# RT58X register map
Series: ARMv8-M Mainline; File version: 1.0
CPU: CM3 r0p0, little endian, MPU, no FPU, VTOR, 3 interrupt priority bits
Registers are 32-bit, read-write, reset 0x0 unless marked. A register's access mark holds for its fields unless they carry their own. Offsets are from the block's base; [hi:lo] are bit positions.

## TIMER1 — TIMER1 Register block
Base 0xA0800000
0x00 T1_LOAD_REG — The initial value of the timer. Also, the reload value when the timer is in periodic mode.
0x04 T1_VALUE_REG ro — The current value of the timer synchronized to the PCLK domain. Note that in cases where PCLK is slow, this value may significantly differ from the actual internal count.
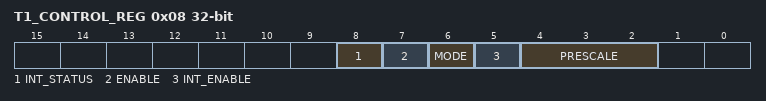
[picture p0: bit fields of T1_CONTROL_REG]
0x08 T1_CONTROL_REG — t1 control
  [8] INT_STATUS ro — Interrupt Status. 0: Timer interrupt is inactive 1: Timer interrupt active.
    0=B_8 (Interrupt Status. 0: Timer interrupt is inactive 1: Timer interrupt active.)
  [7] ENABLE — 0: Timer Disabled 1: Timer Enabled
    0=B_7 (0: Timer Disabled 1: Timer Enabled)
  [6] MODE — 0: Free running mode 1: Periodic mode.
    0=B_6 (0: Free running mode 1: Periodic mode.)
  [5] INT_ENABLE — 0: Timer interrupt disable 1: Timer interrupt enable.
    0=B_5 (0: Timer interrupt disable 1: Timer interrupt enable.)
  [4:2] PRESCALE — 0: clock is divided by one 1: clock is divided by 16 2: clock is divided by 256 3: clock is divided by 2 4: clock is divided by 8 5: clock is divided by 32 6: clock is divided by 128 7: clock is divided by 1024
    0=B_2_to_4 (0: clock is divided by one 1: clock is divided by 16 2: clock is divided by 256 3: clock is divided by 2 4: clock is divided by 8 5: clock is divided by 32 6: clock is divided by 128 7: clock is divided by 1024)
0x0C T1_CLEAR_REG — Clear Interrupt – write any value to clear the timer interrupt.

## WDT — WDT Register block
Base 0xA0900000
0x00 WIN_MAX_REG — This 32-bit value gets loaded into the timer’s counter register and reloaded upon a specific write to the watchdog Kick Register.
0x04 VALUE_REG ro reset 0xFFFF — The current value of the watchdog timer synchronized to the PCLK domain. Note that in cases where PCLK is slow, this value may significantly differ from the actual internal count.
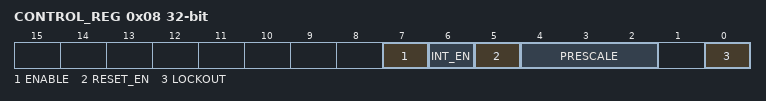
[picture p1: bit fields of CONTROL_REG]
0x08 CONTROL_REG — control
  [7] ENABLE — 0: Timer Disabled 1: Timer Enabled
    0=B_7 (0: Timer Disabled 1: Timer Enabled)
  [6] INT_EN — 0: Interrupt Disabled 1: Interrupt Enabled.
    0=B_6 (0: Interrupt Disabled 1: Interrupt Enabled.)
  [5] RESET_EN — 0: Reset Disabled 1: Reset Enabled.
    0=B_5 (0: Reset Disabled 1: Reset Enabled.)
  [4:2] PRESCALE — 0: clock is divided by one 1: clock is divided by 16 2: clock is divided by 256 3: clock is divided by 32 4: clock is divided by 128 5: clock is divided by 1024 6: clock is divided by 4096 7: clock is divided by 4096
    0=B_2_to_4 (0: clock is divided by one 1: clock is divided by 16 2: clock is divided by 256 3: clock is divided by 32 4: clock is divided by 128 5: clock is divided by 1024 6: clock is divided by 4096 7: clock is divided by 4096)
  [0] LOCKOUT — This bit is the lockOut bit. Write 1’b1 to prevent further configuration changes to the Load, Control, or Reset Occurred Registers.
    0=B_0 (This bit is the lockOut bit. Write 1’b1 to prevent further configuration changes to the Load, Control, or Reset Occurred Registers.)
0x0C KICK_REG — Kick the watchdog - reset the internal timer value to WindowMax and clear the interrupt. Write 0xA5A5 to reload the watchdog timer.
0x10 RESET_OCCUR_REG — reset occur
  [7:0] RESET_OCCUR — resetOccurred counter Writes: If the lockOut bit in the Control Register is 1’b1, writes have no effect. If the lockOut bit is 1’b0, then write any value to the Reset Occurred register to clear the resetOccurred counter. Reads: Read the resetOccurred counter to see how many watchdog reset events have occurred. Note: Counter stops incrementing at 255. Write any value to clear.
    0=B_0_to_7 (resetOccurred counter Writes: If the lockOut bit in the Control Register is 1’b1, writes have no effect. If the lockOut bit is 1’b0, then write any value to the Reset Occurred register to clear the resetOccurred counter. Reads: Read the resetOccurred counter to see how many watchdog reset events have occurred. Note: Counter stops incrementing at 255. Write any value to clear.)
0x14 CLEAR_REG — Write any value to clear intReq interrupt.
0x18 INT_VALUE_REG — This 32-bit value is compared with the timer’s counter register. If they are equal an interrupt is generated.
0x1C WIN_MIN_REG — This 32-bit value feeds a comparator for determining if a write to the watchdog Kick Register has occurred too quickly. 0 means this feature is unused. The feature will also be unused if a value higher than WindowMax is programmed.
